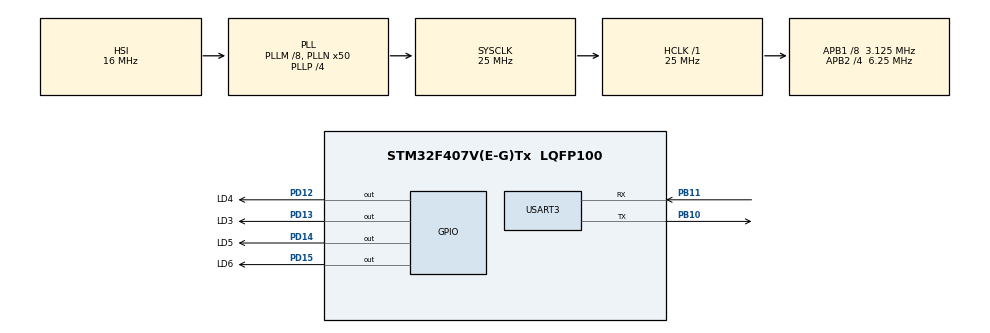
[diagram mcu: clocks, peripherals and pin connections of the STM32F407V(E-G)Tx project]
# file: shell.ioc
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FREERTOS.Tasks01=defaultTask,0,128,StartDefaultTask,Default,NULL,Dynamic,NULL,NULL;CLI,0,512,prvUARTCommandConsoleTask,Default,NULL,Dynamic,NULL,NULL
FREERTOS.configUSE_STATS_FORMATTING_FUNCTIONS=1
FREERTOS.configUSE_TRACE_FACILITY=1
Mcu.Family=STM32F4
Mcu.Name=STM32F407V(E-G)Tx
Mcu.Package=LQFP100
NVIC.PriorityGroup=NVIC_PRIORITYGROUP_4
NVIC.TIM2_IRQn=true\:0\:0\:false\:false\:true\:false\:false
NVIC.TimeBase=TIM2_IRQn
NVIC.TimeBaseIP=TIM2
NVIC.USART3_IRQn=true\:5\:0\:false\:false\:true\:true\:true
PB10.Mode=Asynchronous
PB10.Signal=USART3_TX
PB11.Mode=Asynchronous
PB11.Signal=USART3_RX
PD12.GPIO_Label=LD4
PD12.Signal=GPIO_Output
PD13.GPIO_Label=LD3
PD13.Signal=GPIO_Output
PD14.GPIO_Label=LD5
PD14.Signal=GPIO_Output
PD15.GPIO_Label=LD6
PD15.Signal=GPIO_Output
PH0-OSC_IN.Mode=HSE-External-Oscillator
PH0-OSC_IN.Signal=RCC_OSC_IN
PH1-OSC_OUT.Mode=HSE-External-Oscillator
PH1-OSC_OUT.Signal=RCC_OSC_OUT
ProjectManager.HeapSize=0x2000
ProjectManager.StackSize=0x4000
ProjectManager.TargetToolchain=SW4STM32
RCC.48MHZClocksFreq_Value=14285714.285714285
RCC.AHBFreq_Value=25000000
RCC.APB1CLKDivider=RCC_HCLK_DIV8
RCC.APB1Freq_Value=3125000
RCC.APB1TimFreq_Value=6250000
RCC.APB2CLKDivider=RCC_HCLK_DIV4
RCC.APB2Freq_Value=6250000
RCC.APB2TimFreq_Value=12500000
RCC.CortexFreq_Value=25000000
RCC.HCLKFreq_Value=25000000
RCC.HSE_VALUE=8000000
RCC.HSI_VALUE=16000000
RCC.LSE_VALUE=32768
RCC.PLLM=8
RCC.PLLN=50
RCC.PLLP=RCC_PLLP_DIV4
RCC.PLLQ=7
RCC.SYSCLKFreq_VALUE=25000000
RCC.SYSCLKSource=RCC_SYSCLKSOURCE_PLLCLK
RCC.VCOOutputFreq_Value=100000000
USART3.VirtualMode=VM_ASYNC
VP_FREERTOS_VS_ENABLE.Mode=Enabled
VP_SYS_VS_tim2.Mode=TIM2
board=STM32F4DISCOVERY

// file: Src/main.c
/**
  ******************************************************************************
  * @file           : main.c
  * @brief          : Main program body
  ******************************************************************************
  * This notice applies to any and all portions of this file
  * that are not between comment pairs USER CODE BEGIN and
  * USER CODE END. Other portions of this file, whether
  * inserted by the user or by software development tools
  * are owned by their respective copyright owners.
  *
  * Copyright (c) 2018 STMicroelectronics International N.V.
  * All rights reserved.
  *
  * Redistribution and use in source and binary forms, with or without
  * modification, are permitted, provided that the following conditions are met:
  *
  * 1. Redistribution of source code must retain the above copyright notice,
  *    this list of conditions and the following disclaimer.
  * 2. Redistributions in binary form must reproduce the above copyright notice,
  *    this list of conditions and the following disclaimer in the documentation
  *    and/or other materials provided with the distribution.
  * 3. Neither the name of STMicroelectronics nor the names of other
  *    contributors to this software may be used to endorse or promote products
  *    derived from this software without specific written permission.
  * 4. This software, including modifications and/or derivative works of this
  *    software, must execute solely and exclusively on microcontroller or
  *    microprocessor devices manufactured by or for STMicroelectronics.
  * 5. Redistribution and use of this software other than as permitted under
  *    this license is void and will automatically terminate your rights under
  *    this license.
  *
  * THIS SOFTWARE IS PROVIDED BY STMICROELECTRONICS AND CONTRIBUTORS "AS IS"
  * AND ANY EXPRESS, IMPLIED OR STATUTORY WARRANTIES, INCLUDING, BUT NOT
  * LIMITED TO, THE IMPLIED WARRANTIES OF MERCHANTABILITY, FITNESS FOR A
  * PARTICULAR PURPOSE AND NON-INFRINGEMENT OF THIRD PARTY INTELLECTUAL PROPERTY
  * RIGHTS ARE DISCLAIMED TO THE FULLEST EXTENT PERMITTED BY LAW. IN NO EVENT
  * SHALL STMICROELECTRONICS OR CONTRIBUTORS BE LIABLE FOR ANY DIRECT, INDIRECT,
  * INCIDENTAL, SPECIAL, EXEMPLARY, OR CONSEQUENTIAL DAMAGES (INCLUDING, BUT NOT
  * LIMITED TO, PROCUREMENT OF SUBSTITUTE GOODS OR SERVICES; LOSS OF USE, DATA,
  * OR PROFITS; OR BUSINESS INTERRUPTION) HOWEVER CAUSED AND ON ANY THEORY OF
  * LIABILITY, WHETHER IN CONTRACT, STRICT LIABILITY, OR TORT (INCLUDING
  * NEGLIGENCE OR OTHERWISE) ARISING IN ANY WAY OUT OF THE USE OF THIS SOFTWARE,
  * EVEN IF ADVISED OF THE POSSIBILITY OF SUCH DAMAGE.
  *
  ******************************************************************************
  */
#include "main.h"
#include "stm32f4xx_hal.h"
#include "cmsis_os.h"
#include "usart.h"
#include "gpio.h"

/* USER CODE BEGIN PV */
/* Private variables ---------------------------------------------------------*/

/* USER CODE END PV */

void SystemClock_Config(void);
void MX_FREERTOS_Init(void);

/* USER CODE BEGIN PFP */
/* Private function prototypes -----------------------------------------------*/

/* USER CODE END PFP */

int main(void)
{

  /* MCU Configuration----------------------------------------------------------*/

  /* Reset of all peripherals, Initializes the Flash interface and the Systick. */
  HAL_Init();

  /* Configure the system clock */
  SystemClock_Config();

  /* Initialize all configured peripherals */
  MX_GPIO_Init();
  MX_USART3_UART_Init();

  /* Call init function for freertos objects (in freertos.c) */
  MX_FREERTOS_Init();

  /* Start scheduler */
  osKernelStart();

  /* We should never get here as control is now taken by the scheduler */

  /* Infinite loop */
  while (1)
  {

  }

}

void SystemClock_Config(void)
{

  RCC_OscInitTypeDef RCC_OscInitStruct;
  RCC_ClkInitTypeDef RCC_ClkInitStruct;

    /**Configure the main internal regulator output voltage
    */
  __HAL_RCC_PWR_CLK_ENABLE();

  __HAL_PWR_VOLTAGESCALING_CONFIG(PWR_REGULATOR_VOLTAGE_SCALE1);

    /**Initializes the CPU, AHB and APB busses clocks
    */
  RCC_OscInitStruct.OscillatorType = RCC_OSCILLATORTYPE_HSI;
  RCC_OscInitStruct.HSIState = RCC_HSI_ON;
  RCC_OscInitStruct.HSICalibrationValue = 16;
  RCC_OscInitStruct.PLL.PLLState = RCC_PLL_ON;
  RCC_OscInitStruct.PLL.PLLSource = RCC_PLLSOURCE_HSI;
  RCC_OscInitStruct.PLL.PLLM = 8;
  RCC_OscInitStruct.PLL.PLLN = 50;
  RCC_OscInitStruct.PLL.PLLP = RCC_PLLP_DIV4;
  RCC_OscInitStruct.PLL.PLLQ = 7;
  if (HAL_RCC_OscConfig(&RCC_OscInitStruct) != HAL_OK)
  {
    _Error_Handler(__FILE__, __LINE__);
  }

    /**Initializes the CPU, AHB and APB busses clocks
    */
  RCC_ClkInitStruct.ClockType = RCC_CLOCKTYPE_HCLK|RCC_CLOCKTYPE_SYSCLK
                              |RCC_CLOCKTYPE_PCLK1|RCC_CLOCKTYPE_PCLK2;
  RCC_ClkInitStruct.SYSCLKSource = RCC_SYSCLKSOURCE_PLLCLK;
  RCC_ClkInitStruct.AHBCLKDivider = RCC_SYSCLK_DIV1;
  RCC_ClkInitStruct.APB1CLKDivider = RCC_HCLK_DIV8;
  RCC_ClkInitStruct.APB2CLKDivider = RCC_HCLK_DIV4;

  if (HAL_RCC_ClockConfig(&RCC_ClkInitStruct, FLASH_LATENCY_0) != HAL_OK)
  {
    _Error_Handler(__FILE__, __LINE__);
  }

    /**Configure the Systick interrupt time
    */
  HAL_SYSTICK_Config(HAL_RCC_GetHCLKFreq()/1000);

    /**Configure the Systick
    */
  HAL_SYSTICK_CLKSourceConfig(SYSTICK_CLKSOURCE_HCLK);

  /* SysTick_IRQn interrupt configuration */
  HAL_NVIC_SetPriority(SysTick_IRQn, 15, 0);
}

void HAL_TIM_PeriodElapsedCallback(TIM_HandleTypeDef *htim)
{
  if (htim->Instance == TIM2) {
    HAL_IncTick();
  }
}

void _Error_Handler(char *file, int line)
{
  while(1)
  {
  }
}

/************************ (C) COPYRIGHT STMicroelectronics *****END OF FILE****/

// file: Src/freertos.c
/**
  ******************************************************************************
  * File Name          : freertos.c
  * Description        : Code for freertos applications
  ******************************************************************************
  * This notice applies to any and all portions of this file
  * that are not between comment pairs USER CODE BEGIN and
  * USER CODE END. Other portions of this file, whether
  * inserted by the user or by software development tools
  * are owned by their respective copyright owners.
  *
  * Copyright (c) 2018 STMicroelectronics International N.V.
  * All rights reserved.
  *
  * Redistribution and use in source and binary forms, with or without
  * modification, are permitted, provided that the following conditions are met:
  *
  * 1. Redistribution of source code must retain the above copyright notice,
  *    this list of conditions and the following disclaimer.
  * 2. Redistributions in binary form must reproduce the above copyright notice,
  *    this list of conditions and the following disclaimer in the documentation
  *    and/or other materials provided with the distribution.
  * 3. Neither the name of STMicroelectronics nor the names of other
  *    contributors to this software may be used to endorse or promote products
  *    derived from this software without specific written permission.
  * 4. This software, including modifications and/or derivative works of this
  *    software, must execute solely and exclusively on microcontroller or
  *    microprocessor devices manufactured by or for STMicroelectronics.
  * 5. Redistribution and use of this software other than as permitted under
  *    this license is void and will automatically terminate your rights under
  *    this license.
  *
  * THIS SOFTWARE IS PROVIDED BY STMICROELECTRONICS AND CONTRIBUTORS "AS IS"
  * AND ANY EXPRESS, IMPLIED OR STATUTORY WARRANTIES, INCLUDING, BUT NOT
  * LIMITED TO, THE IMPLIED WARRANTIES OF MERCHANTABILITY, FITNESS FOR A
  * PARTICULAR PURPOSE AND NON-INFRINGEMENT OF THIRD PARTY INTELLECTUAL PROPERTY
  * RIGHTS ARE DISCLAIMED TO THE FULLEST EXTENT PERMITTED BY LAW. IN NO EVENT
  * SHALL STMICROELECTRONICS OR CONTRIBUTORS BE LIABLE FOR ANY DIRECT, INDIRECT,
  * INCIDENTAL, SPECIAL, EXEMPLARY, OR CONSEQUENTIAL DAMAGES (INCLUDING, BUT NOT
  * LIMITED TO, PROCUREMENT OF SUBSTITUTE GOODS OR SERVICES; LOSS OF USE, DATA,
  * OR PROFITS; OR BUSINESS INTERRUPTION) HOWEVER CAUSED AND ON ANY THEORY OF
  * LIABILITY, WHETHER IN CONTRACT, STRICT LIABILITY, OR TORT (INCLUDING
  * NEGLIGENCE OR OTHERWISE) ARISING IN ANY WAY OUT OF THE USE OF THIS SOFTWARE,
  * EVEN IF ADVISED OF THE POSSIBILITY OF SUCH DAMAGE.
  *
  ******************************************************************************
  */

#include "FreeRTOS.h"
#include "task.h"
#include "cmsis_os.h"

/* USER CODE BEGIN Includes */
#include "main.h"
#include "shell.h"
/* USER CODE END Includes */

osThreadId defaultTaskHandle;
osThreadId CLIHandle;

void StartDefaultTask(void const * argument);
void prvUARTCommandConsoleTask(void const * argument);

void MX_FREERTOS_Init(void); /* (MISRA C 2004 rule 8.1) */

/* Hook prototypes */

/* Init FreeRTOS */

void MX_FREERTOS_Init(void) {

  /* Create the thread(s) */
  /* definition and creation of defaultTask */
  osThreadDef(defaultTask, StartDefaultTask, osPriorityNormal, 0, 128);
  defaultTaskHandle = osThreadCreate(osThread(defaultTask), NULL);

  /* definition and creation of CLI */
  osThreadDef(CLI, prvUARTCommandConsoleTask, osPriorityNormal, 0, 512);
  CLIHandle = osThreadCreate(osThread(CLI), NULL);

  /* USER CODE BEGIN RTOS_THREADS */
  /* add threads, ... */
  vRegisterSampleCLICommands();
  /* USER CODE END RTOS_THREADS */

}

/* StartDefaultTask function */
void StartDefaultTask(void const * argument)
{

	for (;;) {
		osDelay(1);
	}
}

/* prvUARTCommandConsoleTask function */
void prvUARTCommandConsoleTask(void const * argument)
{
  /* USER CODE BEGIN prvUARTCommandConsoleTask */
	 /* Infinite loop */
//	for (;;) {
//		HAL_GPIO_TogglePin(LD3_GPIO_Port,LD3_Pin);
//		osDelay(1000);
//	}

	shell_start();
  /* USER CODE END prvUARTCommandConsoleTask */
}

/************************ (C) COPYRIGHT STMicroelectronics *****END OF FILE****/
